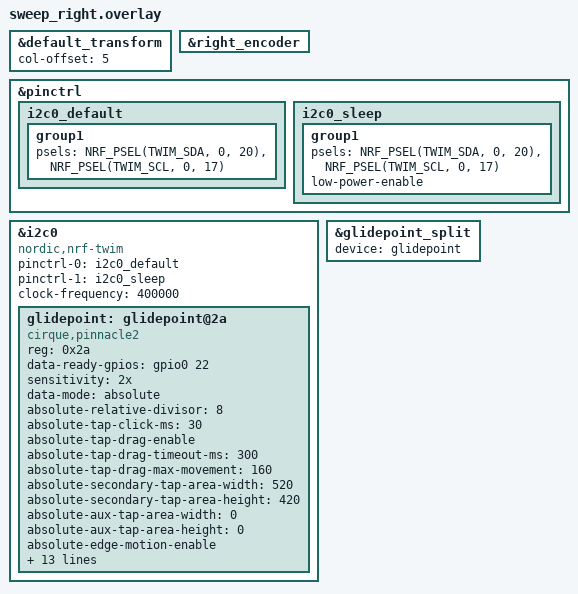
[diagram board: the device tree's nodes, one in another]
#include "sweep.dtsi"

&default_transform {
	col-offset = <5>;
};

&right_encoder {
	status = "okay";
};

&pinctrl {
	/* configuration for i2c0 device, default state */
	i2c0_default: i2c0_default {
		group1 {
			psels = <NRF_PSEL(TWIM_SDA, 0, 20)>,
			<NRF_PSEL(TWIM_SCL, 0, 17)>;
		};
	};
	
	i2c0_sleep: i2c0_sleep {
		group1 {
			psels = <NRF_PSEL(TWIM_SDA, 0, 20)>,
			<NRF_PSEL(TWIM_SCL, 0, 17)>;
			low-power-enable;
		};
	};
};

&i2c0 {
	compatible = "nordic,nrf-twim";// I2C controller instead of generic
	status = "okay";
	
	pinctrl-0 = <&i2c0_default>;
	pinctrl-1 = <&i2c0_sleep>;
	pinctrl-names = "default", "sleep";
	
	clock-frequency = <400000>;
	
	glidepoint: glidepoint@2a{
		compatible = "cirque,pinnacle2";
		reg = <0x2a>;
		status = "okay";
		data-ready-gpios = <&gpio0 22 (GPIO_ACTIVE_HIGH)>;
		sensitivity = "2x";
		data-mode = "absolute";
		absolute-relative-divisor = <8>;
		absolute-tap-click-ms = <30>;
		absolute-tap-drag-enable;
		absolute-tap-drag-timeout-ms = <300>;
		absolute-tap-drag-max-movement = <160>;
		absolute-secondary-tap-area-width = <520>;
		absolute-secondary-tap-area-height = <420>;
		absolute-aux-tap-area-width = <0>;
		absolute-aux-tap-area-height = <0>;
		absolute-edge-motion-enable;
		absolute-edge-motion-zone = <120>;
		absolute-edge-motion-speed = <4>;
		absolute-edge-motion-interval-ms = <10>;
		absolute-edge-motion-start-ms = <120>;
		absolute-right-edge-scroll-enable;
		absolute-top-edge-scroll-enable;
		absolute-scroll-zone = <180>;
		absolute-scroll-divisor = <80>;
		startup-delay-ms = <300>;
		primary-tap-enable;
		glide-extend-enable;
		sleep-mode-enable;
		invert-y;
	};
};

&glidepoint_split {
	device = <&glidepoint>;
};
